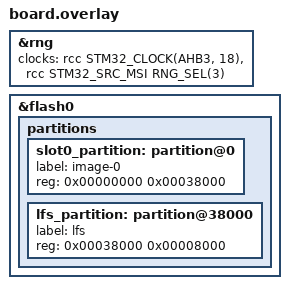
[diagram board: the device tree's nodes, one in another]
/*
 * SPDX-License-Identifier: MIT
 * Seeed Studio LoRa-E5 mini (STM32WLE5JC) -- ZephCore overlay
 *
 * The integrated sub-GHz radio (subghzspi "lora" node), RF switch (PA4/PA5),
 * TCXO and RFO_HP front-end are already fully described in
 * zephyr/dts/arm/seeed_studio/lora-e5.dtsi, and the lora0 alias + USART1
 * console come from the upstream lora_e5_mini board DTS. This overlay only:
 *   1. enables the TRNG entropy source, and
 *   2. repartitions the 256KB internal flash for a bootloader-less ZephCore
 *      image plus a LittleFS data volume.
 */

/*
 * STM32WL TRNG -- entropy source for the CSPRNG used by Ed25519 key
 * generation and LoRa contention jitter. STM32WL has only a raw TRNG;
 * CONFIG_CSPRNG_ENABLED (stm32wl_common.conf) layers the CS generator on top.
 *
 * The RNG functional clock MUST be routed to MSI here. The SoC-default RNG
 * clock source is PLLQ, but this board runs MSI-only (48MHz, msi-range 11)
 * with NO PLL -- so with the default source the RNG domain is unclocked, the
 * driver trips RNG_CR CECS ("clock too slow"), and entropy init fails (an
 * __ASSERT in debug builds; in production sys_csrand_get() then fails and
 * ZephyrRNG cryptoPanicReboots). MSI is live at 48MHz, matching the RNG
 * nist-config. Upstream nucleo_wl55jc only gets away with a bare enable
 * because it runs the PLL, whose Q output clocks the RNG by default.
 *
 * RNG_SEL(3) selects MSI (RCC_CCIPR RNGSEL = 0b11 = LL_RCC_RNG_CLKSOURCE_MSI).
 * Element 0 is the AHB3 peripheral (bus) clock, kept from the SoC node.
 */
&rng {
	status = "okay";
	clocks = <&rcc STM32_CLOCK(AHB3, 18)>, <&rcc STM32_SRC_MSI RNG_SEL(3)>;
};

/*
 * Flash repartition -- no MCUboot (flashed over SWD/ST-Link; STM32WL has no
 * USB for native DFU/UF2). Total 256KB, 2KB erase pages.
 *
 *   0x00000 - 0x38000 (224KB) Application (slot0, links at flash origin)
 *   0x38000 - 0x40000 ( 32KB) LittleFS /lfs (identity, prefs, contacts)
 *
 * The upstream board reserves mcuboot(48K) + dual 96K slots + 16K storage,
 * whose 96K app slot cannot hold ZephCore -- so we delete and rebuild.
 */
/delete-node/ &boot_partition;
/delete-node/ &slot0_partition;
/delete-node/ &slot1_partition;
/delete-node/ &storage_partition;

&flash0 {
	partitions {
		slot0_partition: partition@0 {
			label = "image-0";
			reg = <0x00000000 0x00038000>;
		};

		lfs_partition: partition@38000 {
			label = "lfs";
			reg = <0x00038000 0x00008000>;
		};
	};
};

/* LittleFS auto-mount at /lfs (defines the &lfs fstab node) */
#include "../../common/filesystem.dtsi"
